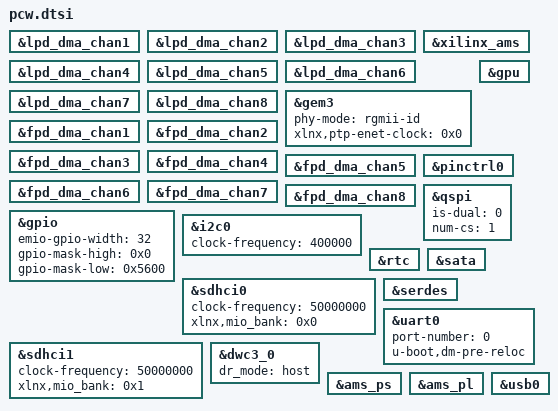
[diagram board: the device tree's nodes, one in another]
/*
 * CAUTION: This file is automatically generated by Xilinx.
 * Version:  
 * Today is: Fri Jun  1 17:03:48 2018
*/


&lpd_dma_chan1 {
	status = "okay";
};
&lpd_dma_chan2 {
	status = "okay";
};
&lpd_dma_chan3 {
	status = "okay";
};
&lpd_dma_chan4 {
	status = "okay";
};
&lpd_dma_chan5 {
	status = "okay";
};
&lpd_dma_chan6 {
	status = "okay";
};
&lpd_dma_chan7 {
	status = "okay";
};
&lpd_dma_chan8 {
	status = "okay";
};
&xilinx_ams {
	status = "okay";
};
&gem3 {
	phy-mode = "rgmii-id";
	status = "okay";
	xlnx,ptp-enet-clock = <0x0>;
};
&fpd_dma_chan1 {
	status = "okay";
};
&fpd_dma_chan2 {
	status = "okay";
};
&fpd_dma_chan3 {
	status = "okay";
};
&fpd_dma_chan4 {
	status = "okay";
};
&fpd_dma_chan5 {
	status = "okay";
};
&fpd_dma_chan6 {
	status = "okay";
};
&fpd_dma_chan7 {
	status = "okay";
};
&fpd_dma_chan8 {
	status = "okay";
};
&gpio {
	emio-gpio-width = <32>;
	gpio-mask-high = <0x0>;
	gpio-mask-low = <0x5600>;
	status = "okay";
};
&gpu {
	status = "okay";
};
&i2c0 {
	clock-frequency = <400000>;
	status = "okay";
};
&pinctrl0 {
	status = "okay";
};
&qspi {
	is-dual = <0>;
	num-cs = <1>;
	status = "okay";
};
&rtc {
	status = "okay";
};
&sata {
	status = "okay";
};
&sdhci0 {
	clock-frequency = <50000000>;
	status = "okay";
	xlnx,mio_bank = <0x0>;
};
&sdhci1 {
	clock-frequency = <50000000>;
	status = "okay";
	xlnx,mio_bank = <0x1>;
};
&serdes {
	status = "okay";
};
&uart0 {
	device_type = "serial";
	port-number = <0>;
	status = "okay";
	u-boot,dm-pre-reloc ;
};
&dwc3_0 {
	dr_mode = "host";
	status = "okay";
};
&ams_ps {
	status = "okay";
};
&ams_pl {
	status = "okay";
};
&usb0 {
	status = "okay";
};
